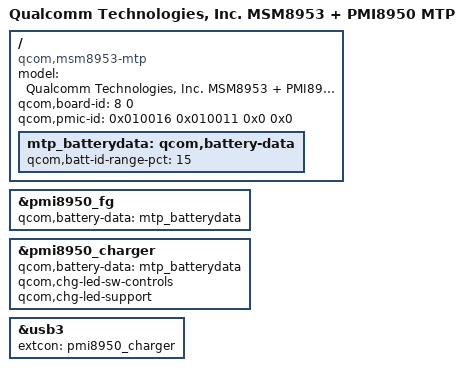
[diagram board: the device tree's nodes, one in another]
/*
 * Copyright (c) 2015-2017, The Linux Foundation. All rights reserved.
 *
 * This program is free software; you can redistribute it and/or modify
 * it under the terms of the GNU General Public License version 2 and
 * only version 2 as published by the Free Software Foundation.
 *
 * This program is distributed in the hope that it will be useful,
 * but WITHOUT ANY WARRANTY; without even the implied warranty of
 * MERCHANTABILITY or FITNESS FOR A PARTICULAR PURPOSE.  See the
 * GNU General Public License for more details.
 */

/dts-v1/;

#include "msm8953.dtsi"
#include "pmi8950.dtsi"
#include "msm8953-mtp.dtsi"
#include "msm8953-pmi8950.dtsi"

/ {
	model = "Qualcomm Technologies, Inc. MSM8953 + PMI8950 MTP";
	compatible = "qcom,msm8953-mtp", "qcom,msm8953", "qcom,mtp";
	qcom,board-id= <8 0>;
	qcom,pmic-id = <0x010016 0x010011 0x0 0x0>;
};

/{
	mtp_batterydata: qcom,battery-data {
		qcom,batt-id-range-pct = <15>;
		#include "batterydata-itech-3000mah.dtsi"
		#include "batterydata-ascent-3450mAh.dtsi"
	};
};

&pmi8950_fg {
	qcom,battery-data = <&mtp_batterydata>;
};

&pmi8950_charger {
	qcom,battery-data = <&mtp_batterydata>;
	qcom,chg-led-sw-controls;
	qcom,chg-led-support;
};

&usb3 {
	extcon = <&pmi8950_charger>;
};
